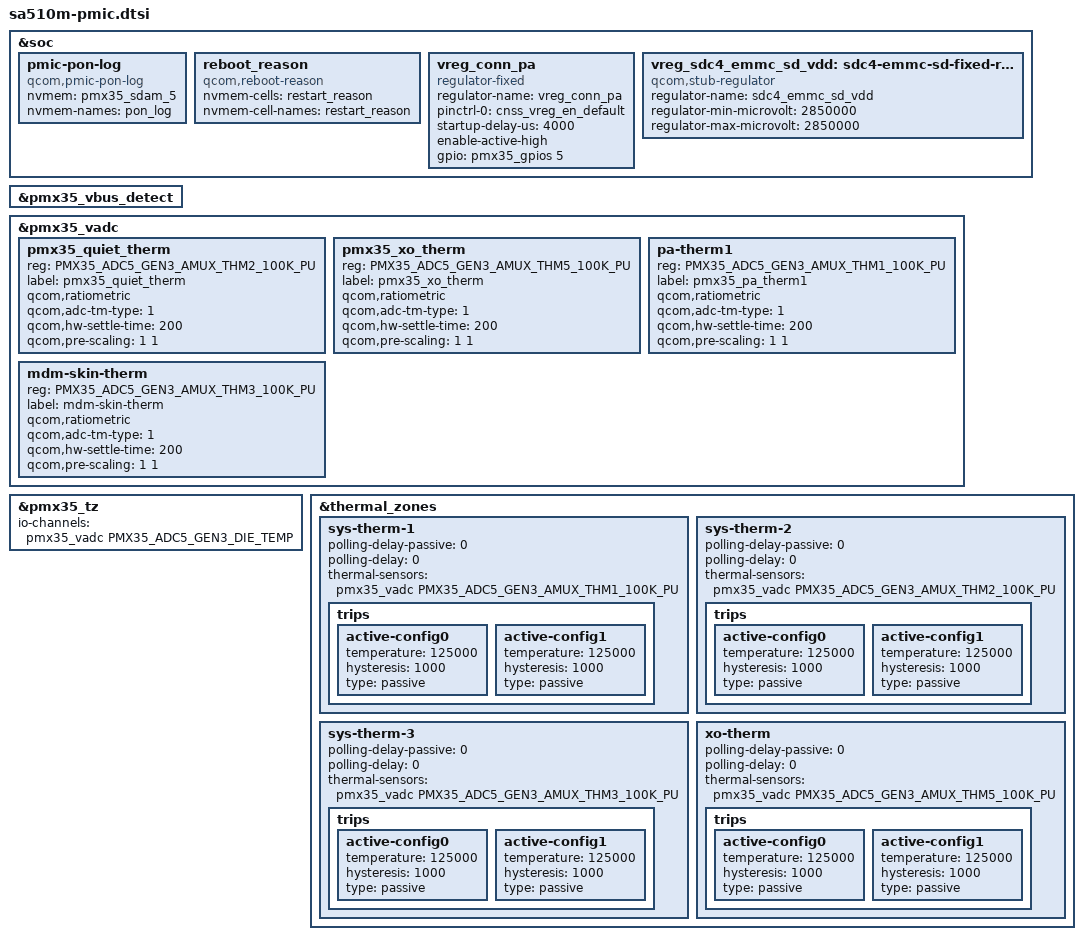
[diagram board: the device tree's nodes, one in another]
// SPDX-License-Identifier: BSD-3-Clause
/*
 * Copyright (c) Qualcomm Technologies, Inc. and/or its subsidiaries.
 */

#include <dt-bindings/pinctrl/qcom,pmic-gpio.h>
#include <dt-bindings/iio/qcom,spmi-vadc.h>
#include "pmx35.dtsi"

&soc {
	pmic-pon-log {
		compatible = "qcom,pmic-pon-log";
		nvmem = <&pmx35_sdam_5>;
		nvmem-names = "pon_log";
	};

	reboot_reason {
		compatible = "qcom,reboot-reason";
		nvmem-cells = <&restart_reason>;
		nvmem-cell-names = "restart_reason";
	};

	vreg_conn_pa: vreg_conn_pa {
		compatible = "regulator-fixed";
		regulator-name = "vreg_conn_pa";
		pinctrl-names = "default";
		pinctrl-0 = <&cnss_vreg_en_default>;
		startup-delay-us = <4000>;
		enable-active-high;
		gpio = <&pmx35_gpios 5 GPIO_ACTIVE_HIGH>;
	};

	vreg_sdc4_emmc_sd_vdd: sdc4-emmc-sd-fixed-regulator {
		compatible = "qcom,stub-regulator";
		regulator-name = "sdc4_emmc_sd_vdd";
		regulator-min-microvolt = <2850000>;
		regulator-max-microvolt = <2850000>;
	};
};

&pmx35_vbus_detect {
	status = "okay";
};

&pmx35_vadc {
	status = "okay";
	pmx35_quiet_therm {
		reg = <PMX35_ADC5_GEN3_AMUX_THM2_100K_PU>;
		label = "pmx35_quiet_therm";
		qcom,ratiometric;
		qcom,adc-tm-type = <1>;
		qcom,hw-settle-time = <200>;
		qcom,pre-scaling = <1 1>;
	};

	pmx35_xo_therm {
		reg = <PMX35_ADC5_GEN3_AMUX_THM5_100K_PU>;
		label = "pmx35_xo_therm";
		qcom,ratiometric;
		qcom,adc-tm-type = <1>;
		qcom,hw-settle-time = <200>;
		qcom,pre-scaling = <1 1>;
	};

	pa-therm1 {
		reg = <PMX35_ADC5_GEN3_AMUX_THM1_100K_PU>;
		label = "pmx35_pa_therm1";
		qcom,ratiometric;
		qcom,adc-tm-type = <1>;
		qcom,hw-settle-time = <200>;
		qcom,pre-scaling = <1 1>;
	};

	mdm-skin-therm {
		reg = <PMX35_ADC5_GEN3_AMUX_THM3_100K_PU>;
		label = "mdm-skin-therm";
		qcom,ratiometric;
		qcom,adc-tm-type = <1>;
		qcom,hw-settle-time = <200>;
		qcom,pre-scaling = <1 1>;
	};

};

&pmx35_tz {
	io-channels = <&pmx35_vadc PMX35_ADC5_GEN3_DIE_TEMP>;
	io-channel-names = "thermal";
};

&thermal_zones {
	sys-therm-1 {
		polling-delay-passive = <0>;
		polling-delay = <0>;
		thermal-sensors = <&pmx35_vadc PMX35_ADC5_GEN3_AMUX_THM1_100K_PU>;
		trips {
			active-config0 {
				temperature = <125000>;
				hysteresis = <1000>;
				type = "passive";
			};

			active-config1 {
				temperature = <125000>;
				hysteresis = <1000>;
				type = "passive";
			};
		};
	};

	sys-therm-2 {
		polling-delay-passive = <0>;
		polling-delay = <0>;
		thermal-sensors = <&pmx35_vadc PMX35_ADC5_GEN3_AMUX_THM2_100K_PU>;
		trips {
			active-config0 {
				temperature = <125000>;
				hysteresis = <1000>;
				type = "passive";
			};

			active-config1 {
				temperature = <125000>;
				hysteresis = <1000>;
				type = "passive";
			};
		};
	};

	sys-therm-3 {
		polling-delay-passive = <0>;
		polling-delay = <0>;
		thermal-sensors = <&pmx35_vadc PMX35_ADC5_GEN3_AMUX_THM3_100K_PU>;
		trips {
			active-config0 {
				temperature = <125000>;
				hysteresis = <1000>;
				type = "passive";
			};

			active-config1 {
				temperature = <125000>;
				hysteresis = <1000>;
				type = "passive";
			};
		};
	};

	xo-therm {
		polling-delay-passive = <0>;
		polling-delay = <0>;
		thermal-sensors = <&pmx35_vadc PMX35_ADC5_GEN3_AMUX_THM5_100K_PU>;
		trips {
			active-config0 {
				temperature = <125000>;
				hysteresis = <1000>;
				type = "passive";
			};

			active-config1 {
				temperature = <125000>;
				hysteresis = <1000>;
				type = "passive";
			};
		};
	};
};
